# Cortex_M55 register map
Vendor: ARM Ltd.; File version: 1.2
Cortex-M55 core descriptions, generated from ARM developer studio
CPU: CM55 r0p0, little endian, MPU, FPU, vendor SysTick, 8 interrupt priority bits
Registers are 32-bit, read-write, no defined reset value unless marked. A register's access mark holds for its fields unless they carry their own. Offsets are from the block's base; lines under a group give offsets from that group; [hi:lo] are bit positions; {n}, {i} and the like mark numbered series; 'fields as' and 'values as' point back to an identical list; <NAME> marks a mode.

## Memory map
0xE000E004 ICB size 0x60 — Interrupt Control Registers
0xE000E010 SYST size 0x180 — SysTick Control Registers
0xE000E100 NVIC size 0x205DC — Nested Vectored Interrupt Controller registers
0xE000ED00 SCB size 0x20090 — System Control Block
0xE000ED90 MPU size 0x20038 — Memory protection Unit Control Registers
0xE000EDD0 SAU size 0xE0 — Security Attribute Unit
0xE000EDF0 DCB size 0x20010 — Debug Registers
0xE000EF00 SIG size 0x20004 — Software Interrupt Control
0xE000EF34 FPE size 0x20018 — Floating Point Control Registers
0xE000EF50 CM size 0x2002C — Cache Maintenance Operations
0xE000EFB0 DIB size 0x20050 — Identification Registers

## CM — Cache Maintenance Operations
Base 0xE000EF50
0x00 ICIALLU wo
  [31:0] Ignored
0x08 ICIMVAU wo
  [31:0] ADDRESS
0x0C DCIMVAC wo
  [31:0] ADDRESS
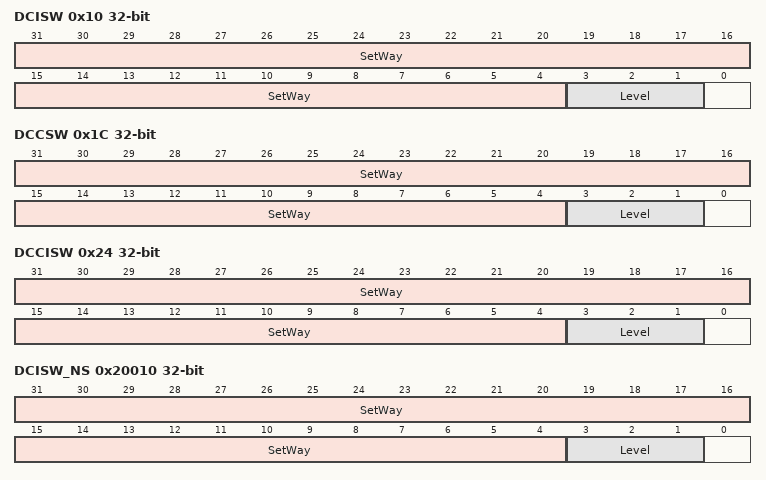
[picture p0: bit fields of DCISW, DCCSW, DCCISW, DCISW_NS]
0x10 DCISW wo
  [31:4] SetWay, [3:1] Level
0x14 DCCMVAU wo
  [31:0] ADDRESS
0x18 DCCMVAC wo
  [31:0] ADDRESS
0x1C DCCSW wo
  [31:4] SetWay, [3:1] Level
0x20 DCCIMVAC wo
  [31:0] ADDRESS
0x24 DCCISW wo
  [31:4] SetWay, [3:1] Level
0x28 BPIALL wo
  [31:0] Ignored
0x20000 ICIALLU_NS wo
  [31:0] Ignored
0x20008 ICIMVAU_NS wo
  [31:0] ADDRESS
0x2000C DCIMVAC_NC wo
  [31:0] ADDRESS
0x20010 DCISW_NS wo
  [31:4] SetWay, [3:1] Level
0x20014 DCCMVAU_NS wo
  [31:0] ADDRESS
0x20018 DCCMVAC_NS wo
  [31:0] ADDRESS
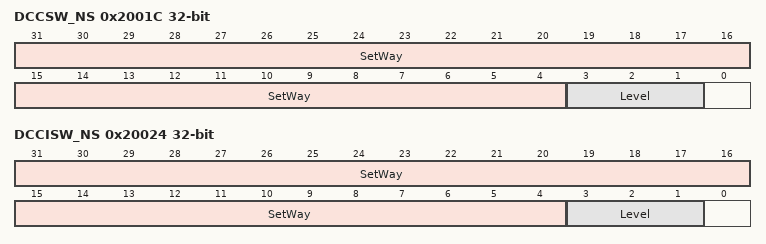
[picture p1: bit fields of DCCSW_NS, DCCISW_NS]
0x2001C DCCSW_NS wo
  [31:4] SetWay, [3:1] Level
0x20020 DCCIMVAC_NS wo
  [31:0] ADDRESS
0x20024 DCCISW_NS wo
  [31:4] SetWay, [3:1] Level
0x20028 BPIALL_NS wo — BPIALL_NS200
  [31:0] Ignored

## DCB — Debug Registers
Base 0xE000EDF0
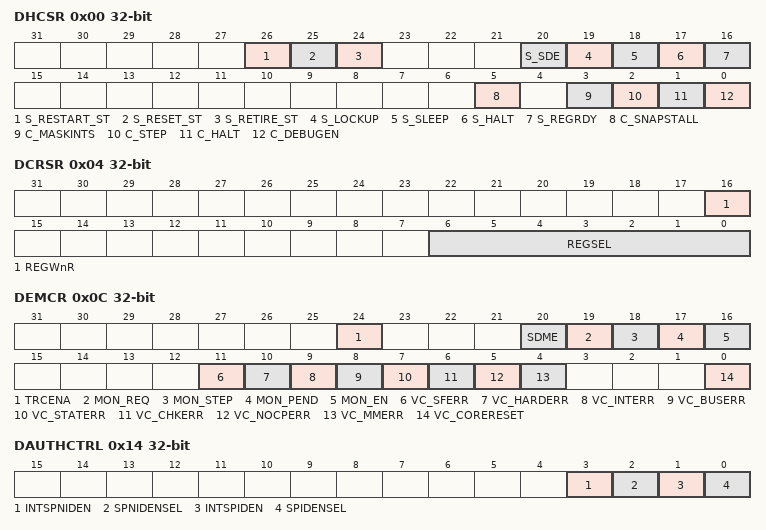
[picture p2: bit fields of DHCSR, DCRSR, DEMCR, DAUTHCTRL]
0x00 DHCSR
  [26] S_RESTART_ST, [25] S_RESET_ST, [24] S_RETIRE_ST, [20] S_SDE, [19] S_LOCKUP, [18] S_SLEEP, [17] S_HALT, [16] S_REGRDY, [5] C_SNAPSTALL, [3] C_MASKINTS, [2] C_STEP, [1] C_HALT, [0] C_DEBUGEN
0x04 DCRSR wo
  [16] REGWnR, [6:0] REGSEL
0x08 DCRDR
  [31:0] DBGTMP
0x0C DEMCR ro
  [24] TRCENA, [20] SDME, [19] MON_REQ, [18] MON_STEP, [17] MON_PEND, [16] MON_EN, [11] VC_SFERR, [10] VC_HARDERR, [9] VC_INTERR, [8] VC_BUSERR, [7] VC_STATERR, [6] VC_CHKERR, [5] VC_NOCPERR, [4] VC_MMERR, [0] VC_CORERESET
0x14 DAUTHCTRL
  [3] INTSPNIDEN, [2] SPNIDENSEL, [1] INTSPIDEN, [0] SPIDENSEL
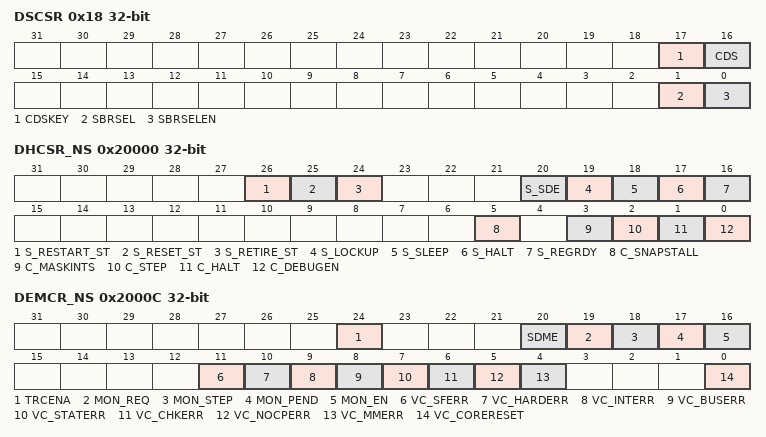
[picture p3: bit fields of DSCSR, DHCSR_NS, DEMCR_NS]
0x18 DSCSR ro
  [17] CDSKEY, [16] CDS, [1] SBRSEL, [0] SBRSELEN
0x20000 DHCSR_NS
  fields as DHCSR
0x2000C DEMCR_NS ro
  fields as DEMCR

## DIB — Identification Registers
Base 0xE000EFB0
0x00 DLAR_S wo
  [31:0] KEY
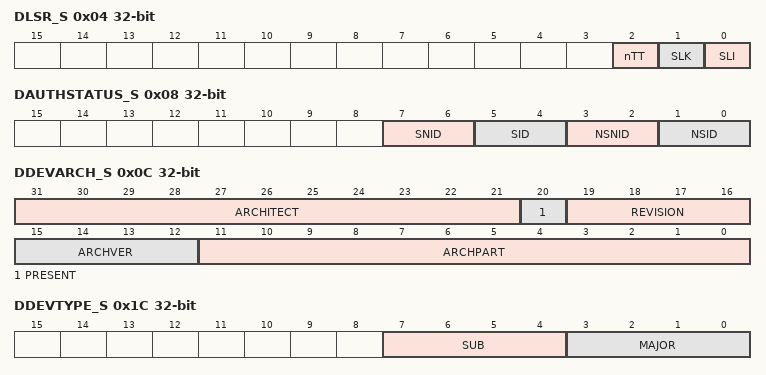
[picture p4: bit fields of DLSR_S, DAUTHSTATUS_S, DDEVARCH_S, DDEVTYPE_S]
0x04 DLSR_S ro
  [2] nTT, [1] SLK, [0] SLI
0x08 DAUTHSTATUS_S ro
  [7:6] SNID, [5:4] SID, [3:2] NSNID, [1:0] NSID
0x0C DDEVARCH_S ro
  [31:21] ARCHITECT, [20] PRESENT, [19:16] REVISION, [15:12] ARCHVER, [11:0] ARCHPART
0x1C DDEVTYPE_S ro
  [7:4] SUB — Sub-type
  [3:0] MAJOR
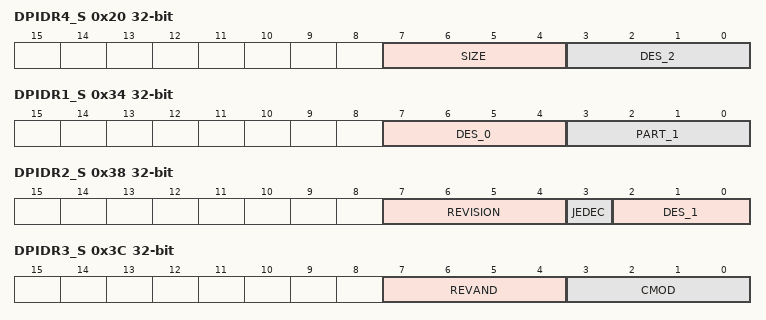
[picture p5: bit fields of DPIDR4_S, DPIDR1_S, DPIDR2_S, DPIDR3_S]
0x20 DPIDR4_S ro
  [7:4] SIZE — 4KB count
  [3:0] DES_2
0x30 DPIDR0_S ro
  [7:0] PART_0
0x34 DPIDR1_S ro
  [7:4] DES_0, [3:0] PART_1
0x38 DPIDR2_S ro
  [7:4] REVISION, [3] JEDEC, [2:0] DES_1
0x3C DPIDR3_S ro
  [7:4] REVAND, [3:0] CMOD
0x40 DCIDR0_S ro
  [7:0] PRMBL_0
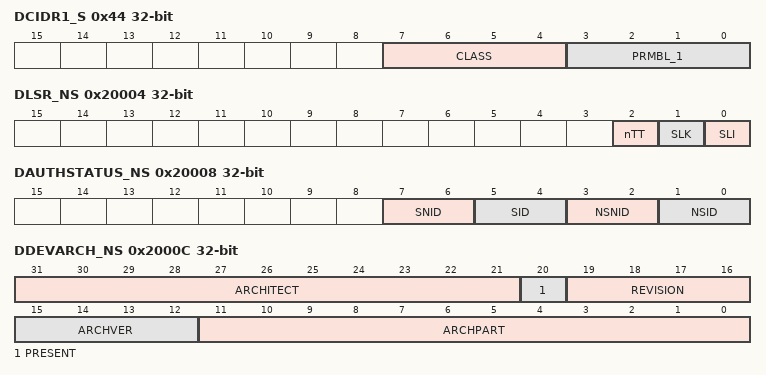
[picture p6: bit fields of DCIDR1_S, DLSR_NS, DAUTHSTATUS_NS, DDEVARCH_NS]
0x44 DCIDR1_S ro
  [7:4] CLASS, [3:0] PRMBL_1
0x48 DCIDR2_S ro
  [7:0] PRMBL_2
0x4C DCIDR3_S ro
  [7:0] PRMBL_3
0x20000 DLAR_NS wo
  [31:0] KEY
0x20004 DLSR_NS ro
  [2] nTT, [1] SLK, [0] SLI
0x20008 DAUTHSTATUS_NS ro
  [7:6] SNID, [5:4] SID, [3:2] NSNID, [1:0] NSID
0x2000C DDEVARCH_NS ro
  fields as DDEVARCH_S
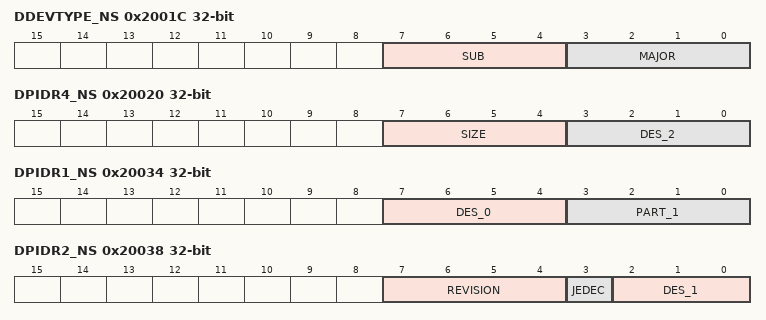
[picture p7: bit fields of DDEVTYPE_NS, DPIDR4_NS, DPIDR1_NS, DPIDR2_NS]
0x2001C DDEVTYPE_NS ro
  [7:4] SUB — Sub-type
  [3:0] MAJOR
0x20020 DPIDR4_NS ro
  [7:4] SIZE — 4KB count
  [3:0] DES_2
0x20030 DPIDR0_NS ro
  [7:0] PART_0
0x20034 DPIDR1_NS ro
  [7:4] DES_0, [3:0] PART_1
0x20038 DPIDR2_NS ro
  [7:4] REVISION, [3] JEDEC, [2:0] DES_1
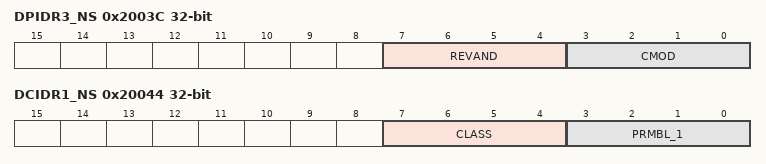
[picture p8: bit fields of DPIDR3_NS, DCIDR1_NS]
0x2003C DPIDR3_NS ro
  [7:4] REVAND, [3:0] CMOD
0x20040 DCIDR0_NS ro
  [7:0] PRMBL_0
0x20044 DCIDR1_NS ro
  [7:4] CLASS, [3:0] PRMBL_1
0x20048 DCIDR2_NS ro
  [7:0] PRMBL_2
0x2004C DCIDR3_NS ro
  [7:0] PRMBL_3

## Notices in the file
Copyright (c) 2025 STMicroelectronics.
SPDX-License-Identifier: Apache-2.0
Licensed under the Apache License, Version 2.0 (the "License");
you may not use this file except in compliance with the License.
You may obtain a copy of the License at
http://www.apache.org/licenses/LICENSE-2.0
Unless required by applicable law or agreed to in writing, software
distributed under the License is distributed on an "AS IS" BASIS,
WITHOUT WARRANTIES OR CONDITIONS OF ANY KIND, either express or implied.
See the License for the specific language governing permissions and
limitations under the License.
